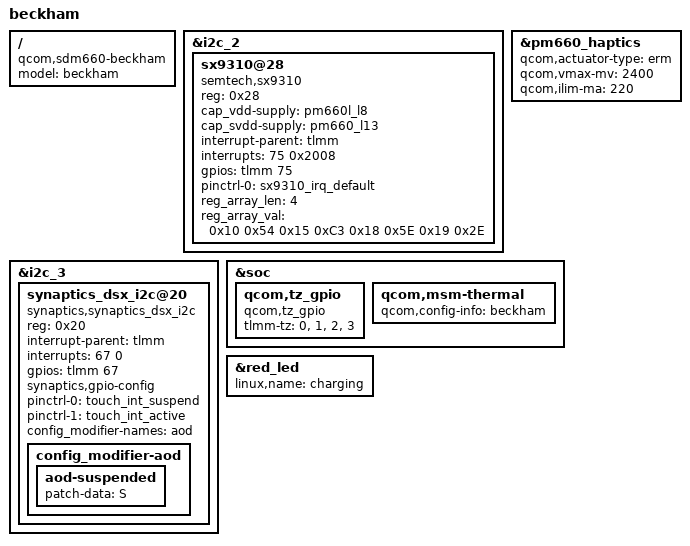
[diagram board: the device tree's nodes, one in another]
/* Copyright (c) 2016, Motorola Mobility Inc. All rights reserved.
 *
 * This program is free software; you can redistribute it and/or modify
 * it under the terms of the GNU General Public License version 2 and
 * only version 2 as published by the Free Software Foundation.
 *
 * This program is distributed in the hope that it will be useful,
 * but WITHOUT ANY WARRANTY; without even the implied warranty of
 * MERCHANTABILITY or FITNESS FOR A PARTICULAR PURPOSE.  See the
 * GNU General Public License for more details.
 */

#include "sdm660-moto-common.dtsi"
#include "sdm660-external-codec.dtsi"
#include "sdm660-beckham-pinctrl.dtsi"

/ {
	model = "beckham";
	compatible = "qcom,sdm660-beckham", "qcom,sdm660-moto",
			"qcom,sdm660";
};

&i2c_2 { /* BLSP1 CAP SENSOR */
	status = "okay";
	sx9310@28 {
		compatible = "semtech,sx9310";
		reg = <0x28>;
		cap_vdd-supply = <&pm660l_l8>;
		cap_svdd-supply = <&pm660_l13>;
		interrupt-parent = <&tlmm>;
		interrupts = <75 0x2008>;
		gpios = <&tlmm 75 0x2008>; /* IRQ */
		pinctrl-names = "default";
		pinctrl-0 = <&sx9310_irq_default>;
		reg_array_len = <4>;
		reg_array_val = <0x10 0x54 0x15 0xC3 0x18 0x5E 0x19 0x2E>;
	};
};

&i2c_3 {
	synaptics_dsx_i2c@20 {
		compatible = "synaptics,synaptics_dsx_i2c";
		reg = <0x20>;
		interrupt-parent = <&tlmm>;
		interrupts = <67 0>;
		gpios = <&tlmm 67 0>; /* IRQ */
		synaptics,gpio-config;
		pinctrl-names = "default", "active";
		pinctrl-0 = <&touch_int_suspend>;
		pinctrl-1 = <&touch_int_active>;
		config_modifier-names = "aod";
		config_modifier-aod {
			aod-suspended {
				/* Power->sleep; */
				patch-data = "S";
			};
		};
	};
};

&pm660_haptics { /* Vibrator */
	qcom,actuator-type = "erm";
	qcom,vmax-mv = <2400>;
	qcom,ilim-ma = <220>;

	/delete-property/ qcom,lra-high-z;
	/delete-property/ qcom,lra-auto-res-mode;
	/delete-property/ qcom,lra-res-cal-period;
};

&soc{
	qcom,tz_gpio {
		compatible = "qcom,tz_gpio";
		tlmm-tz = <0>,
			<1>,
			<2>,
			<3>;
	};

	qcom,msm-thermal {
		qcom,config-info = "beckham";
	};
};

&red_led {
	linux,name = "charging";
	/delete-property/ linux,default-trigger;
};

/delete-node/ &green_led;
/delete-node/ &blue_led;
